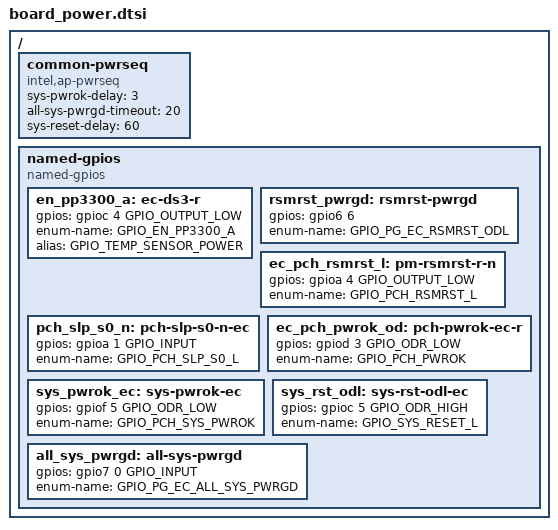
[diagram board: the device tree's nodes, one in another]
/* Copyright 2024 The ChromiumOS Authors
 * Use of this source code is governed by a BSD-style license that can be
 * found in the LICENSE file.
 */

#include <npcx_emul.dts>
#include "mtlrvp_npcx.h"

/ {
	common-pwrseq {
		compatible = "intel,ap-pwrseq";

		sys-pwrok-delay = <3>;
		all-sys-pwrgd-timeout = <20>;
		sys-reset-delay = <60>;
	};

	named-gpios {
		compatible = "named-gpios";

		en_pp3300_a: ec-ds3-r {
			gpios = <&gpioc 4 GPIO_OUTPUT_LOW>;
			enum-name = "GPIO_EN_PP3300_A";
			alias = "GPIO_TEMP_SENSOR_POWER";
		};

		rsmrst_pwrgd: rsmrst-pwrgd {
			gpios = <&gpio6 6 (GPIO_INPUT | GPIO_VOLTAGE_1P8)>;
			enum-name = "GPIO_PG_EC_RSMRST_ODL";
		};

		ec_pch_rsmrst_l: pm-rsmrst-r-n {
			gpios = <&gpioa 4 GPIO_OUTPUT_LOW>; /* 1.8V */
			enum-name = "GPIO_PCH_RSMRST_L";
		};

		pch_slp_s0_n: pch-slp-s0-n-ec {
			gpios = <&gpioa 1 GPIO_INPUT>;
			enum-name = "GPIO_PCH_SLP_S0_L"; /* 1.8V */
		};

		ec_pch_pwrok_od: pch-pwrok-ec-r {
			gpios = <&gpiod 3 GPIO_ODR_LOW>;
			enum-name = "GPIO_PCH_PWROK";
		};

		sys_pwrok_ec: sys-pwrok-ec {
			gpios = <&gpiof 5 GPIO_ODR_LOW>;
			enum-name = "GPIO_PCH_SYS_PWROK";
		};

		sys_rst_odl: sys-rst-odl-ec {
			gpios = <&gpioc 5 GPIO_ODR_HIGH>;
			enum-name = "GPIO_SYS_RESET_L";
		};

		all_sys_pwrgd: all-sys-pwrgd {
			gpios = <&gpio7 0 GPIO_INPUT>;
			enum-name = "GPIO_PG_EC_ALL_SYS_PWRGD";
		};

	};
};


#include "../mtlrvp/power_signals.dtsi"
